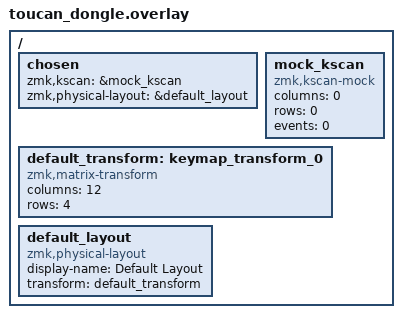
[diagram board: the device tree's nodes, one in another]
// Match the hardware module's include order: keys.h also defines RC().
#include <dt-bindings/zmk/keys.h>
#include <dt-bindings/zmk/matrix_transform.h>
#include <physical_layouts.dtsi>

/ {
    chosen {
        zmk,kscan = &mock_kscan;
        zmk,physical-layout = &default_layout;
    };

    // Key positions arrive from the halves; do not configure their GPIOs here.
    mock_kscan: mock_kscan {
        compatible = "zmk,kscan-mock";
        columns = <0>;
        rows = <0>;
        events = <0>;
    };

    // The shared Toucan keymap supplies the same 36-position map and geometry
    // as the halves, including their inactive outer thumbs.
    default_transform: keymap_transform_0 {
        compatible = "zmk,matrix-transform";
        columns = <12>;
        rows = <4>;
    };

    default_layout: default_layout {
        compatible = "zmk,physical-layout";
        display-name = "Default Layout";
        transform = <&default_transform>;
    };
};
